AUTOSAR XML (schema 4-2-2)
package /Components
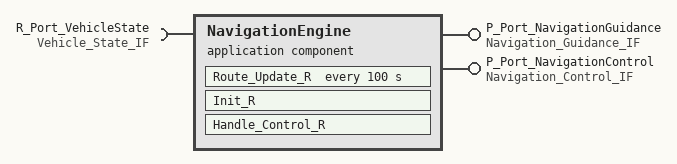
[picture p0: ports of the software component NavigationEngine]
  application sw component type NavigationEngine
    provide port P_Port_NavigationGuidance: provided-interface=Navigation_Guidance_IF
    provide port P_Port_NavigationControl: provided-interface=Navigation_Control_IF
    require port R_Port_VehicleState: required-interface=Vehicle_State_IF
    behavior NavigationEngine_Internal
      init event Navigation_Init: start-on-event=Init_R
      operation invoked event NavigationControl_Called: start-on-event=Handle_Control_R
      timing event Navigation_Periodic: start-on-event=Route_Update_R, period=100
      runnable Init_R: symbol=NavigationEngine_Init
        parameter access Param_DefaultTurnType: accessed-parameter=P_Port_NavigationGuidance.turn_type
        parameter access Param_DefaultLaneRecommendation: accessed-parameter=P_Port_NavigationGuidance.lane_recommendation
      runnable Route_Update_R: minimum-start-interval=100, symbol=NavigationEngine_Route_Update
        data-read-access:
          access Read_VehicleSpeed: accessed-variable=R_Port_VehicleState.vehicle_speed_kph
          access Read_VehicleGear: accessed-variable=R_Port_VehicleState.vehicle_gear
        data-send-points:
          access Send_TurnType: accessed-variable=P_Port_NavigationGuidance.turn_type
          access Send_DistanceToTurn: accessed-variable=P_Port_NavigationGuidance.distance_to_turn_m
          access Send_LaneRecommendation: accessed-variable=P_Port_NavigationGuidance.lane_recommendation
      runnable Handle_Control_R: symbol=NavigationEngine_Handle_Control
        data-write-access:
          access Write_TurnType: accessed-variable=P_Port_NavigationGuidance.turn_type
          access Write_DistanceToTurn: accessed-variable=P_Port_NavigationGuidance.distance_to_turn_m
          access Write_LaneRecommendation: accessed-variable=P_Port_NavigationGuidance.lane_recommendation
